# GD32H7xx register map
File version: 1.0
CPU: CM7 r1p2, little endian, MPU, FPU, 4 interrupt priority bits
Registers are 32-bit, read-write, reset 0x0 unless marked. A register's access mark holds for its fields unless they carry their own. Offsets are from the block's base; [hi:lo] are bit positions.

## ENET0_PTP — Ethernet: Precision time protocol
Base 0x40028700
Same registers: ENET1_PTP 0x4002A700
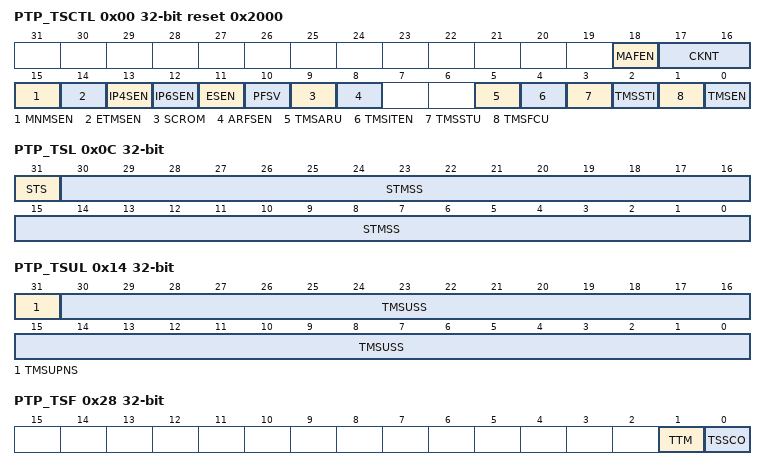
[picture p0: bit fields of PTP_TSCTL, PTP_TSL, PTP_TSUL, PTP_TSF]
0x00 PTP_TSCTL reset 0x2000 — Ethernet PTP time stamp control register (PTP_TSCTL)
  [18] MAFEN — MAC address filter enable for PTP frame
  [17:16] CKNT — Clock node type for time stamp
  [15] MNMSEN — Received master node message snapshot enable
  [14] ETMSEN — Received event type message snapshot enable
  [13] IP4SEN — Received IPv4 snapshot enable
  [12] IP6SEN — Received IPv6 snapshot enable
  [11] ESEN — Received Ethernet snapshot enable
  [10] PFSV — PTP frame snooping version
  [9] SCROM — Subsecond counter rollover mode
  [8] ARFSEN — All received frames snapshot enable
  [5] TMSARU — Time stamp addend register update
  [4] TMSITEN — Time stamp interrupt trigger enable
  [3] TMSSTU — Time stamp system time update
  [2] TMSSTI — Time stamp system time initialize
  [1] TMSFCU — Time stamp fine or coarse update
  [0] TMSEN — Time stamp enable
0x04 PTP_SSINC — Ethernet PTP subsecond increment register
  [7:0] STMSSI — System time subsecond increment
0x08 PTP_TSH ro — Ethernet PTP time stamp high register
  [31:0] STMS — System time second
0x0C PTP_TSL ro — Ethernet PTP time stamp low register (PTP_TSL)
  [31] STS — System time sign
  [30:0] STMSS — System time subseconds
0x10 PTP_TSUH — Ethernet PTP time stamp high update register
  [31:0] TMSUS — Time stamp update second
0x14 PTP_TSUL — Ethernet PTP time stamp low update register (PTP_TSUL)
  [31] TMSUPNS — Time stamp update positive or negative sign
  [30:0] TMSUSS — Time stamp update subseconds
0x18 PTP_TSADDEND — Ethernet PTP time stamp addend register
  [31:0] TMSA — Time stamp addend
0x1C PTP_ETH — Ethernet PTP expected time high register
  [31:0] ETSH — Expected time stamp high
0x20 PTP_ETL — Ethernet PTP expected time low register
  [31:0] ETSL — Expected time stamp low
0x28 PTP_TSF ro — Ethernet PTP time stamp flag register
  [1] TTM — Target time match
  [0] TSSCO — Timestamp second counter overflow
0x2C PTP_PPSCTL — Ethernet PTP PPS control register
  [3:0] PPSOFC — PPS output frequency configure

## EDOUT — En-coder Divided-Output controller
Base 0x40018800
0x00 CTL — Control register
  [0] POL — The active polarity of the B-phase output signal selection
0x04 ENABLE
  [0] EDOUTEN — EDOUT enable bit
0x08 LOC — Location register
  [15:0] LOCMAX — This bits set the maximum location value for one rotation
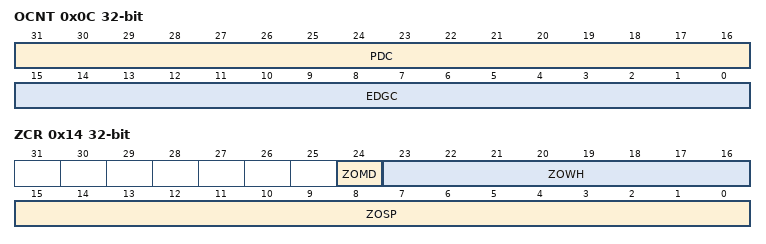
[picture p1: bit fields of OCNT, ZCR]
0x0C OCNT — Output counter register
  [31:16] PDC — These bits set the phase difference between the A-phase signal and the B-phase signal for the next carrier cycle
  [15:0] EDGC — These bits set the number of edges of the A-phase signal and the B-phase signal for the next carrier cycle
0x10 LCNT — Location counter register
  [15:0] LOCCNT — These bits are used to set the current position value
0x14 ZCR — Z-PHASE configure register
  [24] ZOMD — Z-PHASE output mode
  [23:16] ZOWH — Z-PHASE output width
  [15:0] ZOSP — Z-PHASE output start position

## FAC — Filter arithmetic accelerator
Base 0x48024800
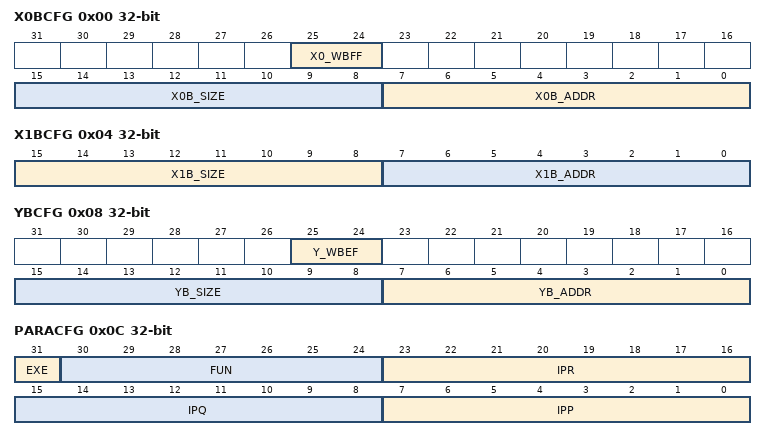
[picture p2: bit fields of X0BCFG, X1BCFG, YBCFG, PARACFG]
0x00 X0BCFG — FAC X0 buffer configure register
  [25:24] X0_WBFF — Buffer full flag of watermark
  [15:8] X0B_SIZE — X0 buffer size, the number of feed-forward taps
  [7:0] X0B_ADDR — X0 buffer base address
0x04 X1BCFG — FAC X1 buffer configure register
  [15:8] X1B_SIZE — X1 buffer size
  [7:0] X1B_ADDR — X1 buffer base address
0x08 YBCFG — FAC Y buffer configure register
  [25:24] Y_WBEF — Buffer empty flag of watermark
  [15:8] YB_SIZE — Y buffer size
  [7:0] YB_ADDR — Y buffer base address
0x0C PARACFG — FAC Parameter configure register
  [31] EXE — Execution
  [30:24] FUN — Function
  [23:16] IPR — Input parameter IPR
  [15:8] IPQ — Input parameter IPQ
  [7:0] IPP — Input parameter IPP
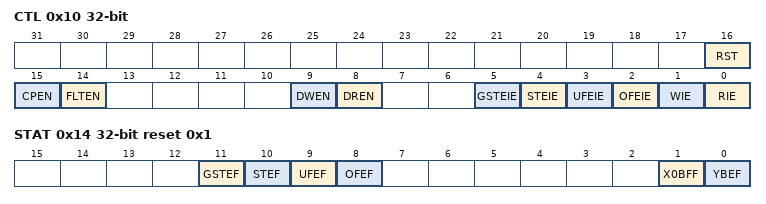
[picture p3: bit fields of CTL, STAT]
0x10 CTL — FAC Control register
  [16] RST — Reset FAC unit
  [15] CPEN — Clipping enable
  [14] FLTEN — Floating point format enable
  [9] DWEN — DMA write channel enable
  [8] DREN — DMA read channel enable
  [5] GSTEIE — Gain saturation error interrupt enable
  [4] STEIE — Saturation error interrupt enable
  [3] UFEIE — Underflow error interrupt enable
  [2] OFEIE — Overflow error interrupt enable
  [1] WIE — Write interrupt enable
  [0] RIE — Read interrupt enable
0x14 STAT ro reset 0x1 — FAC Status register
  [11] GSTEF — Gain saturation error flag, it is set when gain exceed range
  [10] STEF — Saturation error flag
  [9] UFEF — Underflow error flag
  [8] OFEF — Overflow error flag
  [1] X0BFF — X0 buffer full flag
  [0] YBEF — Y buffer empty flag
0x18 WDATA — FAC write data register
  [31:0] WDATA — Write data
0x1C RDATA — FAC read data register
  [31:0] RDATA — Read data
